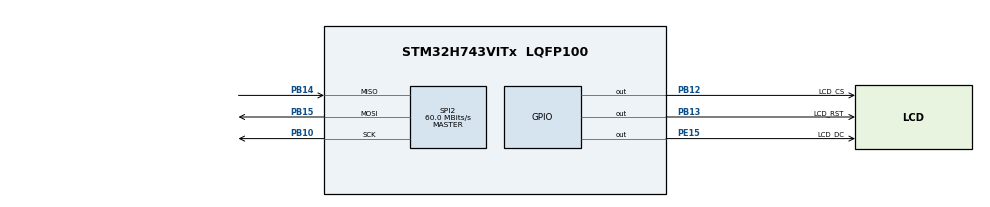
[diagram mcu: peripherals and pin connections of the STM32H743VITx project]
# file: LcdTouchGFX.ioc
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CORTEX_M7.CPU_DCache=Enabled
CORTEX_M7.CPU_ICache=Enabled
Mcu.Family=STM32H7
Mcu.Name=STM32H743VITx
Mcu.Package=LQFP100
NVIC.PriorityGroup=NVIC_PRIORITYGROUP_4
PA13\ (JTMS/SWDIO).Mode=Serial_Wire
PA13\ (JTMS/SWDIO).Signal=DEBUG_JTMS-SWDIO
PA14\ (JTCK/SWCLK).Mode=Serial_Wire
PA14\ (JTCK/SWCLK).Signal=DEBUG_JTCK-SWCLK
PB10.GPIO_Speed=GPIO_SPEED_FREQ_VERY_HIGH
PB10.Mode=Full_Duplex_Master
PB10.Signal=SPI2_SCK
PB12.GPIO_Label=LCD_CS
PB12.GPIO_Speed=GPIO_SPEED_FREQ_VERY_HIGH
PB12.PinState=GPIO_PIN_SET
PB12.Signal=GPIO_Output
PB13.GPIO_Label=LCD_RST
PB13.GPIO_Speed=GPIO_SPEED_FREQ_VERY_HIGH
PB13.Signal=GPIO_Output
PB14.GPIO_Speed=GPIO_SPEED_FREQ_VERY_HIGH
PB14.Mode=Full_Duplex_Master
PB14.Signal=SPI2_MISO
PB15.GPIO_Speed=GPIO_SPEED_FREQ_VERY_HIGH
PB15.Mode=Full_Duplex_Master
PB15.Signal=SPI2_MOSI
PE15.GPIO_Label=LCD_DC
PE15.GPIO_Speed=GPIO_SPEED_FREQ_VERY_HIGH
PE15.PinState=GPIO_PIN_SET
PE15.Signal=GPIO_Output
PH0-OSC_IN\ (PH0).Mode=HSE-External-Oscillator
PH0-OSC_IN\ (PH0).Signal=RCC_OSC_IN
PH1-OSC_OUT\ (PH1).Mode=HSE-External-Oscillator
PH1-OSC_OUT\ (PH1).Signal=RCC_OSC_OUT
ProjectManager.HeapSize=0x4000
ProjectManager.StackSize=0x4000
ProjectManager.TargetToolchain=MDK-ARM V5.27
RCC.ADCFreq_Value=50390625
RCC.APB1Freq_Value=120000000
RCC.APB2Freq_Value=120000000
RCC.APB3Freq_Value=120000000
RCC.APB4Freq_Value=120000000
RCC.CortexFreq_Value=480000000
RCC.D1PPRE=RCC_APB3_DIV2
RCC.D2PPRE1=RCC_APB1_DIV2
RCC.D2PPRE2=RCC_APB2_DIV2
RCC.D3PPRE=RCC_APB4_DIV2
RCC.DIVM1=5
RCC.DIVN1=192
RCC.HCLKFreq_Value=240000000
RCC.HPRE=RCC_HCLK_DIV2
RCC.PLL2FRACN=0
RCC.PLL3FRACN=0
RCC.PLLFRACN=0
RCC.PLLSourceVirtual=RCC_PLLSOURCE_HSE
RCC.SYSCLKFreq_VALUE=480000000
RCC.SYSCLKSource=RCC_SYSCLKSOURCE_PLLCLK
RCC.USBFreq_Value=480000000
SPI2.BaudRatePrescaler=SPI_BAUDRATEPRESCALER_8
SPI2.CalculateBaudRate=60.0 MBits/s
SPI2.DataSize=SPI_DATASIZE_8BIT
SPI2.Direction=SPI_DIRECTION_2LINES
SPI2.Mode=SPI_MODE_MASTER
SPI2.VirtualType=VM_MASTER
STMicroelectronics.X-CUBE-TOUCHGFX.4.15.0.ApplicationCcGraphicsJjApplication=TouchGFXOoGenerator
STMicroelectronics.X-CUBE-TOUCHGFX.4.15.0.tgfx_custom_height=240
STMicroelectronics.X-CUBE-TOUCHGFX.4.15.0.tgfx_custom_width=320
STMicroelectronics.X-CUBE-TOUCHGFX.4.15.0.tgfx_hardware_accelerator=dma_none
VP_CRC_VS_CRC.Mode=CRC_Activate
VP_STMicroelectronics.X-CUBE-TOUCHGFX_VS_GraphicsJjApplication_4.15.0.Mode=GraphicsJjApplication
board=custom

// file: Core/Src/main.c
/* USER CODE BEGIN Header */
/**
  ******************************************************************************
  * @file           : main.c
  * @brief          : Main program body
  ******************************************************************************
  * @attention
  *
  * <h2><center>&copy; Copyright (c) 2020 STMicroelectronics.
  * All rights reserved.</center></h2>
  *
  * This software component is licensed by ST under Ultimate Liberty license
  * SLA0044, the "License"; You may not use this file except in compliance with
  * the License. You may obtain a copy of the License at:
  *                             www.st.com/SLA0044
  *
  ******************************************************************************
  */
/* USER CODE END Header */
#include "main.h"
#include "crc.h"
#include "spi.h"
#include "gpio.h"
#include "app_touchgfx.h"

void SystemClock_Config(void);

int main(void)
{

  /* Enable I-Cache---------------------------------------------------------*/
  SCB_EnableICache();

  /* Enable D-Cache---------------------------------------------------------*/
  SCB_EnableDCache();

  /* MCU Configuration--------------------------------------------------------*/

  /* Reset of all peripherals, Initializes the Flash interface and the Systick. */
  HAL_Init();

  /* Configure the system clock */
  SystemClock_Config();

  /* Initialize all configured peripherals */
  MX_GPIO_Init();
  MX_CRC_Init();
  MX_SPI2_Init();
  MX_TouchGFX_Init();
  /* USER CODE BEGIN 2 */
ILI9341_Init();
ILI9341_Fill_Screen(BLACK);
  /* USER CODE END 2 */

  /* Infinite loop */
  while (1)
  {

  MX_TouchGFX_Process();
  }
}

void SystemClock_Config(void)
{
  RCC_OscInitTypeDef RCC_OscInitStruct = {0};
  RCC_ClkInitTypeDef RCC_ClkInitStruct = {0};
  RCC_PeriphCLKInitTypeDef PeriphClkInitStruct = {0};

  /** Supply configuration update enable
  */
  HAL_PWREx_ConfigSupply(PWR_LDO_SUPPLY);
  /** Configure the main internal regulator output voltage
  */
  __HAL_PWR_VOLTAGESCALING_CONFIG(PWR_REGULATOR_VOLTAGE_SCALE0);

  while(!__HAL_PWR_GET_FLAG(PWR_FLAG_VOSRDY)) {}
  /** Initializes the RCC Oscillators according to the specified parameters
  * in the RCC_OscInitTypeDef structure.
  */
  RCC_OscInitStruct.OscillatorType = RCC_OSCILLATORTYPE_HSE;
  RCC_OscInitStruct.HSEState = RCC_HSE_ON;
  RCC_OscInitStruct.PLL.PLLState = RCC_PLL_ON;
  RCC_OscInitStruct.PLL.PLLSource = RCC_PLLSOURCE_HSE;
  RCC_OscInitStruct.PLL.PLLM = 5;
  RCC_OscInitStruct.PLL.PLLN = 192;
  RCC_OscInitStruct.PLL.PLLP = 2;
  RCC_OscInitStruct.PLL.PLLQ = 2;
  RCC_OscInitStruct.PLL.PLLR = 2;
  RCC_OscInitStruct.PLL.PLLRGE = RCC_PLL1VCIRANGE_2;
  RCC_OscInitStruct.PLL.PLLVCOSEL = RCC_PLL1VCOWIDE;
  RCC_OscInitStruct.PLL.PLLFRACN = 0;
  if (HAL_RCC_OscConfig(&RCC_OscInitStruct) != HAL_OK)
  {
    Error_Handler();
  }
  /** Initializes the CPU, AHB and APB buses clocks
  */
  RCC_ClkInitStruct.ClockType = RCC_CLOCKTYPE_HCLK|RCC_CLOCKTYPE_SYSCLK
                              |RCC_CLOCKTYPE_PCLK1|RCC_CLOCKTYPE_PCLK2
                              |RCC_CLOCKTYPE_D3PCLK1|RCC_CLOCKTYPE_D1PCLK1;
  RCC_ClkInitStruct.SYSCLKSource = RCC_SYSCLKSOURCE_PLLCLK;
  RCC_ClkInitStruct.SYSCLKDivider = RCC_SYSCLK_DIV1;
  RCC_ClkInitStruct.AHBCLKDivider = RCC_HCLK_DIV2;
  RCC_ClkInitStruct.APB3CLKDivider = RCC_APB3_DIV2;
  RCC_ClkInitStruct.APB1CLKDivider = RCC_APB1_DIV2;
  RCC_ClkInitStruct.APB2CLKDivider = RCC_APB2_DIV2;
  RCC_ClkInitStruct.APB4CLKDivider = RCC_APB4_DIV2;

  if (HAL_RCC_ClockConfig(&RCC_ClkInitStruct, FLASH_LATENCY_4) != HAL_OK)
  {
    Error_Handler();
  }
  PeriphClkInitStruct.PeriphClockSelection = RCC_PERIPHCLK_SPI2;
  PeriphClkInitStruct.Spi123ClockSelection = RCC_SPI123CLKSOURCE_PLL;
  if (HAL_RCCEx_PeriphCLKConfig(&PeriphClkInitStruct) != HAL_OK)
  {
    Error_Handler();
  }
}

void Error_Handler(void)
{
}

/************************ (C) COPYRIGHT STMicroelectronics *****END OF FILE****/
